# SAM3X8E register map
File version: 0
Registers are 32-bit, read-write, reset 0x0 unless marked. A register's access mark holds for its fields unless they carry their own. Offsets are from the block's base; [hi:lo] are bit positions; 'fields as' and 'values as' point back to an identical list.

## CHIPID — Chip Identifier
Base 0x400E0940; register names take the prefix CHIPID_
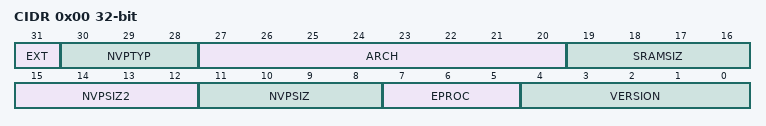
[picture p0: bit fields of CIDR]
0x00 CIDR ro reset not defined — Chip ID Register
  [31] EXT — Extension Flag
  [30:28] NVPTYP — Nonvolatile Program Memory Type
    0=ROM; 1=ROMLESS (ROMless or on-chip Flash); 2=FLASH (Embedded Flash Memory); 3=ROM_FLASH (ROM and Embedded Flash MemoryNVPSIZ is ROM size NVPSIZ2 is Flash size); 4=SRAM (SRAM emulating ROM)
  [27:20] ARCH — Architecture Identifier
    25=AT91SAM9xx Series; 41=AT91SAM9XExx Series; 52=AT91x34 Series; 55=CAP7 (CAP7 Series); 57=CAP9 (CAP9 Series); 59=CAP11 (CAP11 Series); 64=AT91x40 Series; 66=AT91x42 Series; 85=AT91x55 Series; 96=AT91SAM7Axx Series; 97=AT91SAM7AQxx Series; 99=AT91x63 Series; 112=AT91SAM7Sxx Series; 113=AT91SAM7XCxx Series; 114=AT91SAM7SExx Series; 115=AT91SAM7Lxx Series; 117=AT91SAM7Xxx Series; 118=AT91SAM7SLxx Series; 128=SAM3UxC Series (100-pin version); 129=SAM3UxE Series (144-pin version); 131=SAM3AxC Series (100-pin version); 131=SAM4AxC Series (100-pin version); 132=SAM3XxC Series (100-pin version); 132=SAM4XxC Series (100-pin version); 133=SAM3XxE Series (144-pin version); 133=SAM4XxE Series (144-pin version); 134=SAM3XxG Series (208/217-pin version); 134=SAM4XxG Series (208/217-pin version); 136=SAM3SxASeries (48-pin version); 136=SAM4SxA Series (48-pin version); 137=SAM3SxB Series (64-pin version); 137=SAM4SxB Series (64-pin version); 138=SAM3SxC Series (100-pin version); 138=SAM4SxC Series (100-pin version); 146=AT91x92 Series; 147=SAM3NxA Series (48-pin version); 148=SAM3NxB Series (64-pin version); 149=SAM3NxC Series (100-pin version); 153=SAM3SDxB Series (64-pin version); 154=SAM3SDxC Series (100-pin version); 165=SAM5A; 240=AT75Cxx Series
  [19:16] SRAMSIZ — Internal SRAM Size
    0=48K (48K bytes); 1=1K (1K bytes); 2=2K (2K bytes); 3=6K (6K bytes); 4=24K (24K bytes); 5=4K (4K bytes); 6=80K (80K bytes); 7=160K (160K bytes); 8=8K (8K bytes); 9=16K (16K bytes); 10=32K (32K bytes); 11=64K (64K bytes); 12=128K (128K bytes); 13=256K (256K bytes); 14=96K (96K bytes); 15=512K (512K bytes)
  [15:12] NVPSIZ2 — Second Nonvolatile Program Memory Size
    0=NONE; 1=8K (8K bytes); 2=16K (16K bytes); 3=32K (32K bytes); 5=64K (64K bytes); 7=128K (128K bytes); 9=256K (256K bytes); 10=512K (512K bytes); 12=1024K (1024K bytes); 14=2048K (2048K bytes)
  [11:8] NVPSIZ — Nonvolatile Program Memory Size
    values as NVPSIZ2
  [7:5] EPROC — Embedded Processor
    1=ARM946ES; 2=ARM7TDMI; 3=CM3 (Cortex-M3); 4=ARM920T; 5=ARM926EJS; 6=CA5 (Cortex-A5); 7=CM4 (Cortex-M4)
  [4:0] VERSION — Version of the Device
0x04 EXID ro reset not defined — Chip ID Extension Register
  [31:0] EXID — Chip ID Extension

## EFC0 — Embedded Flash Controller 0
Base 0x400E0A00; register names take the prefix EFC0_
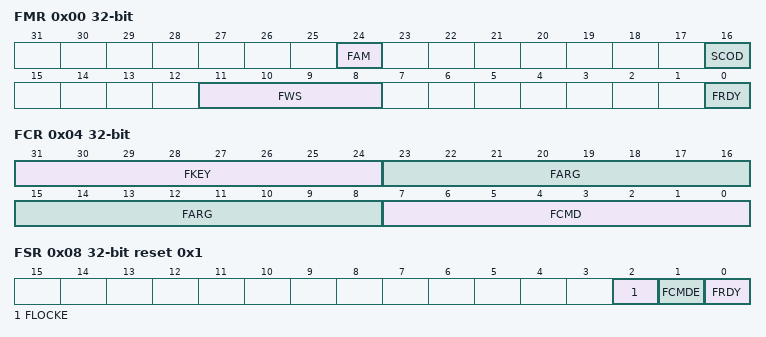
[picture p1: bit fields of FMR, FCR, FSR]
0x00 FMR — EEFC Flash Mode Register
  [24] FAM — Flash Access Mode
  [16] SCOD — Sequential Code Optimization Disable
  [11:8] FWS — Flash Wait State
  [0] FRDY — Ready Interrupt Enable
0x04 FCR wo reset not defined — EEFC Flash Command Register
  [31:24] FKEY — Flash Writing Protection Key
  [23:8] FARG — Flash Command Argument
  [7:0] FCMD — Flash Command
0x08 FSR ro reset 0x1 — EEFC Flash Status Register
  [2] FLOCKE — Flash Lock Error Status
  [1] FCMDE — Flash Command Error Status
  [0] FRDY — Flash Ready Status
0x0C FRR ro — EEFC Flash Result Register
  [31:0] FVALUE — Flash Result Value

## EFC1 — Embedded Flash Controller 1
Base 0x400E0C00; register names take the prefix EFC1_
Registers as EFC0.

## RSTC — Reset Controller
Base 0x400E1A00; register names take the prefix RSTC_
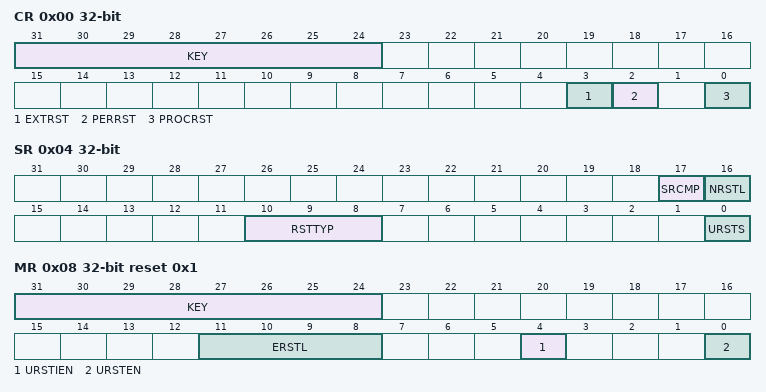
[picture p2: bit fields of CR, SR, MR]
0x00 CR wo reset not defined — Control Register
  [31:24] KEY — Password
  [3] EXTRST — External Reset
  [2] PERRST — Peripheral Reset
  [0] PROCRST — Processor Reset
0x04 SR ro — Status Register
  [17] SRCMP — Software Reset Command in Progress
  [16] NRSTL — NRST Pin Level
  [10:8] RSTTYP — Reset Type
  [0] URSTS — User Reset Status
0x08 MR reset 0x1 — Mode Register
  [31:24] KEY — Password
  [11:8] ERSTL — External Reset Length
  [4] URSTIEN — User Reset Interrupt Enable
  [0] URSTEN — User Reset Enable

## Notices in the file
Copyright (c) 2011, Atmel Corporation
All rights reserved.
Redistribution and use in source and binary forms, with or without
modification, are permitted provided that the following condition is met:
- Redistributions of source code must retain the above copyright notice,
this list of conditions and the disclaimer below.
Atmel's name may not be used to endorse or promote products derived from
this software without specific prior written permission.
DISCLAIMER:  THIS SOFTWARE IS PROVIDED BY ATMEL "AS IS" AND ANY EXPRESS OR
IMPLIED WARRANTIES, INCLUDING, BUT NOT LIMITED TO, THE IMPLIED WARRANTIES OF
MERCHANTABILITY, FITNESS FOR A PARTICULAR PURPOSE AND NON-INFRINGEMENT ARE
DISCLAIMED. IN NO EVENT SHALL ATMEL BE LIABLE FOR ANY DIRECT, INDIRECT,
INCIDENTAL, SPECIAL, EXEMPLARY, OR CONSEQUENTIAL DAMAGES (INCLUDING, BUT NOT
LIMITED TO, PROCUREMENT OF SUBSTITUTE GOODS OR SERVICES; LOSS OF USE, DATA,
OR PROFITS; OR BUSINESS INTERRUPTION) HOWEVER CAUSED AND ON ANY THEORY OF
LIABILITY, WHETHER IN CONTRACT, STRICT LIABILITY, OR TORT (INCLUDING
NEGLIGENCE OR OTHERWISE) ARISING IN ANY WAY OUT OF THE USE OF THIS SOFTWARE,
EVEN IF ADVISED OF THE POSSIBILITY OF SUCH DAMAGE.
